# APP_CFG_QSPI register map
Vendor: Texas Instruments
Peripheral module from a debugger description file (folder xwrl64xx).
Registers are 32-bit, access per field, no defined reset value unless marked. A register's access mark holds for its fields unless they carry their own. Offsets are as the file gives them; lines under a group give offsets from that group; [hi:lo] are bit positions; {n}, {i} and the like mark numbered series; 'fields as' and 'values as' point back to an identical list; <NAME> marks a mode.

## APP_CFG_QSPI
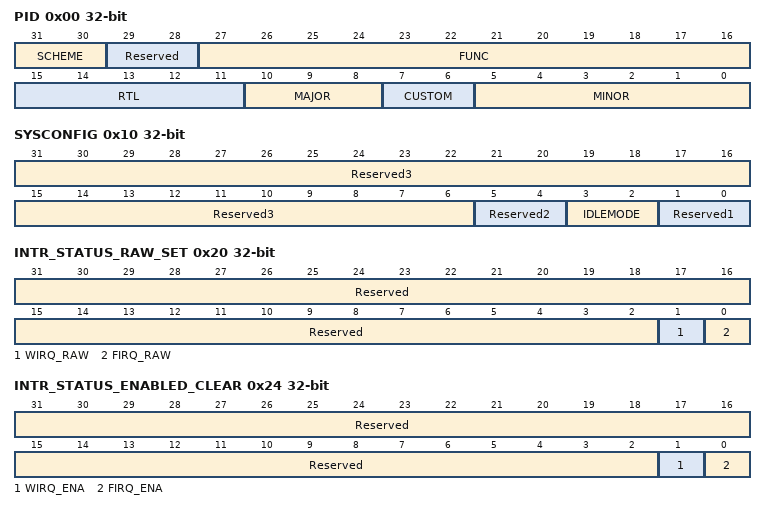
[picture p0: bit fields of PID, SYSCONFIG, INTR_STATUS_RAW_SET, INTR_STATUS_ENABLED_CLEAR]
0x00 PID ro
  [31:30] SCHEME — The scheme of the register used. This indicates the PDR3.5 Method
  [29:28] Reserved — Always read as 0
  [27:16] FUNC — The function of the module being used
  [15:11] RTL — RTL Release Version The PDR release number of this IP
  [10:8] MAJOR — Major Release Number
  [7:6] CUSTOM — Custom IP
  [5:0] MINOR — Minor Release Number
{0x0+4i} MSS_QSPI_Reserved{i} ro (i=1..3) — Reserved
0x10 SYSCONFIG
  [31:6] Reserved3 ro — Always read as 0
  [5:4] Reserved2 ro — Always read as 0
  [3:2] IDLEMODE rw — Configuration of the local target state management mode. By definition, target can handle read/write transaction as long as it is out of IDLE state 0x0 : Force-idle mode: local target's idle state follows (acknowledges) the system's idle requests unconditionally, i.e. regardless of the IP module's internal requirements. Backup mode, for debug only 0x1 : No-idle mode: local target never enters idle state. Backup mode, for debug only 0x2 : Smart-idle mode: local target's idle state eventually follows (acknowledges) the system's idle requests, depending on the IP module's internal requirements. IP module shall not generate (IRQ- or DMA-request-related) wakeup events 0x3 : Smart-idle wakeup-capable mode: local target's idle state eventually follows (acknowledges) the system's idle requests, depending on the IP module's internal requirements. IP module may generate (IRQ- or DMA-request-related) wakeup events when in idle state. Mode is only relevant if the appropriate IP module "swakeup" output(s) is (are) implemented
  [1:0] Reserved1 ro — Always read as 0
{0x4+4i} MSS_QSPI_Reserved{i} ro (i=4..6) — Reserved
0x20 INTR_STATUS_RAW_SET — INTR Interrupt Status Raw/Set Register
  [31:2] Reserved ro — Always read as 0
  [1] WIRQ_RAW rw — Word Interrupt Status Read indicates raw status 0 = inactive 1 = active Writing 1 will set status Writing 0 has no effect
  [0] FIRQ_RAW rw — Frame Interrupt Status Read indicates raw status 0 = inactive 1 = active Writing 1 will set status Writing 0 has no effect
0x24 INTR_STATUS_ENABLED_CLEAR — INTR Interrupt Status Enabled/Clear Register
  [31:2] Reserved ro — Always read as 0
  [1] WIRQ_ENA rw — Word Interrupt Enabled Status Read indicates enabled status 0 = inactive 1 = active Writing 1 will clear interrupt Writing 0 has no effect
  [0] FIRQ_ENA rw — Frame Interrupt Enabled Status Read indicates enabled status 0 = inactive 1 = active Writing 1 will clear interrupt Writing 0 has no effect
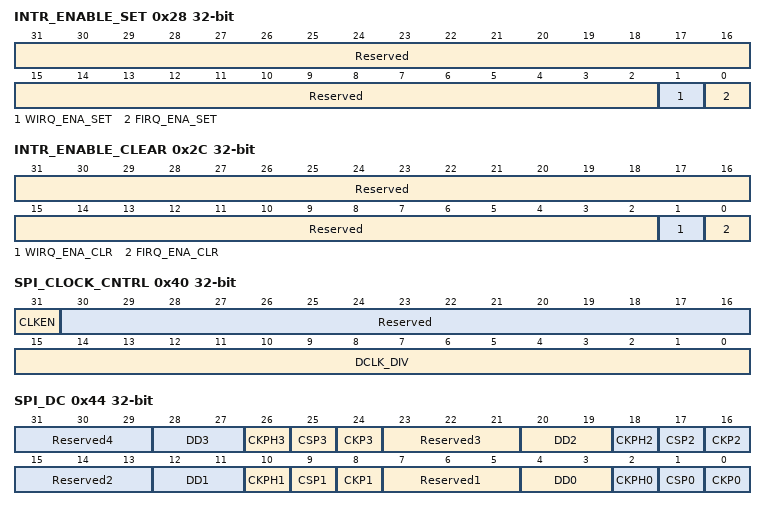
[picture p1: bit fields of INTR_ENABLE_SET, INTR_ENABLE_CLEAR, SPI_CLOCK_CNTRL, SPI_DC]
0x28 INTR_ENABLE_SET — INTR Interrupt Enable/Set Register
  [31:2] Reserved ro — Always read as 0
  [1] WIRQ_ENA_SET rw — Word Interrupt Enable/Set Read indicates interrupt enable 0 = disabled 1 = enabled Writing 1 will set interrupt enabled Writing 0 has no effect
  [0] FIRQ_ENA_SET rw — Frame Interrupt Enable/Set Read indicates interrupt enable 0 = disabled 1 = enabled Writing 1 will set interrupt enabled Writing 0 has no effect
0x2C INTR_ENABLE_CLEAR — INTR Interrupt Enable/Clear Register
  [31:2] Reserved ro — Always read as 0
  [1] WIRQ_ENA_CLR rw — Word Interrupt Enable/Clear Read indicates interrupt enable 0 = disabled 1 = enabled Writing 1 will clear interrupt enabled Writing 0 has no effect
  [0] FIRQ_ENA_CLR rw — Frame Interrupt Enable/Clear Read indicates interrupt enable 0 = disabled 1 = enabled Writing 1 will clear interrupt enabled Writing 0 has no effect
0x30 INTC_EOI rw — EOI Register
  [31:0] EOI_VECTOR — Number associated with the ipgenericirq for intr output. There are 1 interrupt outputs Write 0x0 : Write to intr IP Generic Any other write value is ignored.
{0x18+4i} MSS_QSPI_Reserved{i} ro (i=7..9) — Reserved
0x40 SPI_CLOCK_CNTRL — SPI Clock Control Register (SPICC)
  [31] CLKEN rw — Clock Enable. 0- Data clock is turned off 1- Data clock is enabled
  [30:16] Reserved ro — Always read as 0
  [15:0] DCLK_DIV rw — Serial data clock divide by ratio
0x44 SPI_DC — SPI Data Control Register (SPIDC)
  [8n-1:8n-3] Reserved{n} ro (n=1..4) — Always read as 0
  [8n+4:8n+3] DD{n} rw (n=0..3) — Data delay for chip select {n} 00- Data is output on the same cycle as the CS_N goes active 01- Data is output 1 DCLK cycle after the CS_N goes active 10- Data is output 2 DCLK cycles after the CS_N goes active 11- Data is output 3 DCLK cycles after the CS_N goes active
  [26] CKPH3 rw — Clock phase for chip select 3 If CKP0 = 0 0- Data shifted out on falling edge; input on rising edge 1- Data shifted out on rising edge; input on falling edge If CKP0 = 1 1- Data shifted out on falling edge; input on rising edge 0- Data shifted out on rising edge; input on falling edge
  [8n+1] CSP{n} rw (n=0..3) — Chip select polarity for chip select {n} 0- Active low 1- Active high
  [8n] CKP{n} rw (n=0..3) — Clock polarity for chip select {n} 0- When data is not being transferred, SCK = 0 1- When data is not being transferred, SCK = 1
  [18] CKPH2 rw — Clock phase for chip select 2. If CKP0 = 0 0- Data shifted out on falling edge; input on rising edge 1- Data shifted out on rising edge; input on falling edge If CKP0 = 1 1- Data shifted out on falling edge; input on rising edge 0- Data shifted out on rising edge; input on falling edge
  [10] CKPH1 rw — Clock phase for chip select 1. If CKP0 = 0 0- Data shifted out on falling edge; input on rising edge 1- Data shifted out on rising edge; input on falling edge If CKP0 = 1 1- Data shifted out on falling edge; input on rising edge 0- Data shifted out on rising edge; input on falling edge
  [2] CKPH0 rw — Clock phase for chip select 0. If CKP0 = 0 0- Data shifted out on falling edge; input on rising edge 1- Data shifted out on rising edge; input on falling edge If CKP0 = 1 1- Data shifted out on falling edge; input on rising edge 0- Data shifted out on rising edge; input on falling edge
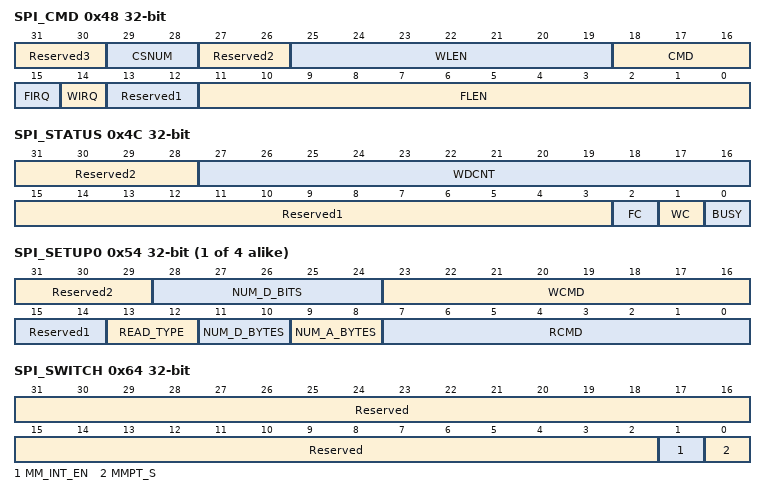
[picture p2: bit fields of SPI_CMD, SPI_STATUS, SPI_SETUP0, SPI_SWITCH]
0x48 SPI_CMD — SPI Command Register (SPICR)
  [31:30] Reserved3 ro — Always read as 0
  [29:28] CSNUM rw — Device select. Sets the active chip select for the transfer 00- Chip Select 0 active 01- Chip Select 1 active 10- Chip Select 2 active 11- Chip Select 3 active
  [27:26] Reserved2 ro — Always read as 0
  [25:19] WLEN rw — Word length. Sets the size of the individual transfers from 1 – 128 bits 0- 1 bit 1- 2 bits … 127 – 128 bits
  [18:16] CMD rw — Transfer command 000- Reserved 001- 4 pin Read Single 010- 4 pin Write Single 011- 4 pin Read Dual 100 – Reserved 101 – 3 pin Read Single 110 – 3 pin Write Single 111 – 6 pin Read Quad
  [15] FIRQ rw — Frame count interrupt enable
  [14] WIRQ rw — Word count interrupt enable
  [13:12] Reserved1 ro — Always read as 0
  [11:0] FLEN rw — Frame Length 0- 1 word 1- 2 words … 4095 – 4096 words
0x4C SPI_STATUS ro — SPI Status Register (SPISR)
  [31:28] Reserved2 — Always read as 0
  [27:16] WDCNT — Word count. This field will reflect the 1-4096 words transferred
  [15:3] Reserved1 — Always read as 0
  [2] FC — Frame complete. This bit is set after all of the requested words have been transmitted. 0- Transfer is not complete 1- Transfer is complete This bit is reset when the SPI Status Register is read
  [1] WC — Word complete. This bit is set after each word transfer is completed. 0- Word transfer is not complete 1- Word transfer is complete This bit is reset when the SPI Status Register is read
  [0] BUSY — Busy bit. Active transfer in progress. This bit is only set during an active word transfer. Between words, the bit will clear to signal that it is ok to read/write the data registers. 0- Idle 1- Busy
0x50 SPI_DATA rw — SPI Data Register (SPIDR)
  [31:0] DATA — Data register for read and write operations
{0x54+4i} SPI_SETUP{i} (i=0..3) — Memory Mapped SPI Setup{i} Register
  [31:29] Reserved2 ro — Always read as 0
  [28:24] NUM_D_BITS rw — Number of dummy bits to use if NUM_D_BYTES = 0
  [23:16] WCMD rw — Write Command
  [15:14] Reserved1 ro — Always read as 0
  [13:12] READ_TYPE rw — Determines if the read command is a single, dual or quad read mode command 00 – Normal read (all data input on spi_din) 01 – Dual read (odd bytes input on spi_din; even on spi_dout) 10 – Normal read (all data input on spi_din) 11 – Quad read (uses spi_qdin0/1)
  [11:10] NUM_D_BYTES rw — Number of dummy bytes to be used for fast read. 0 = use the value in NUM_D_BITS 1 = use 8 bits; 2 = use 16 bits; 3 = use 24 bits
  [9:8] NUM_A_BYTES rw — Number of address bytes to be sent. 0 = 1 byte; 1 = 2 bytes; 2 = 3 bytes; 3 = 4 bytes
  [7:0] RCMD rw — Read Command
0x64 SPI_SWITCH — Memory Mapped SPI Switch Register
  [31:2] Reserved ro — Always read as 0
  [1] MM_INT_EN rw — Memory Mapped mode interrupt enable. 0 – Interrupts are disabled during memory mapped operations 1 – Word Count interrupt is enabled for memory mapped operations
  [0] MMPT_S rw — MMPT select. If 0 (default) config port has is selected to control config of core SPI module. If 1, Memory Mapped Protocol Translator is selected to control config port of core SPI module.
{0x64+4i} SPI_DATA{i} rw (i=1..3) — SPI Data Register (SPIDR{i})
  [31:0] DATA — Data register for read and write operations
